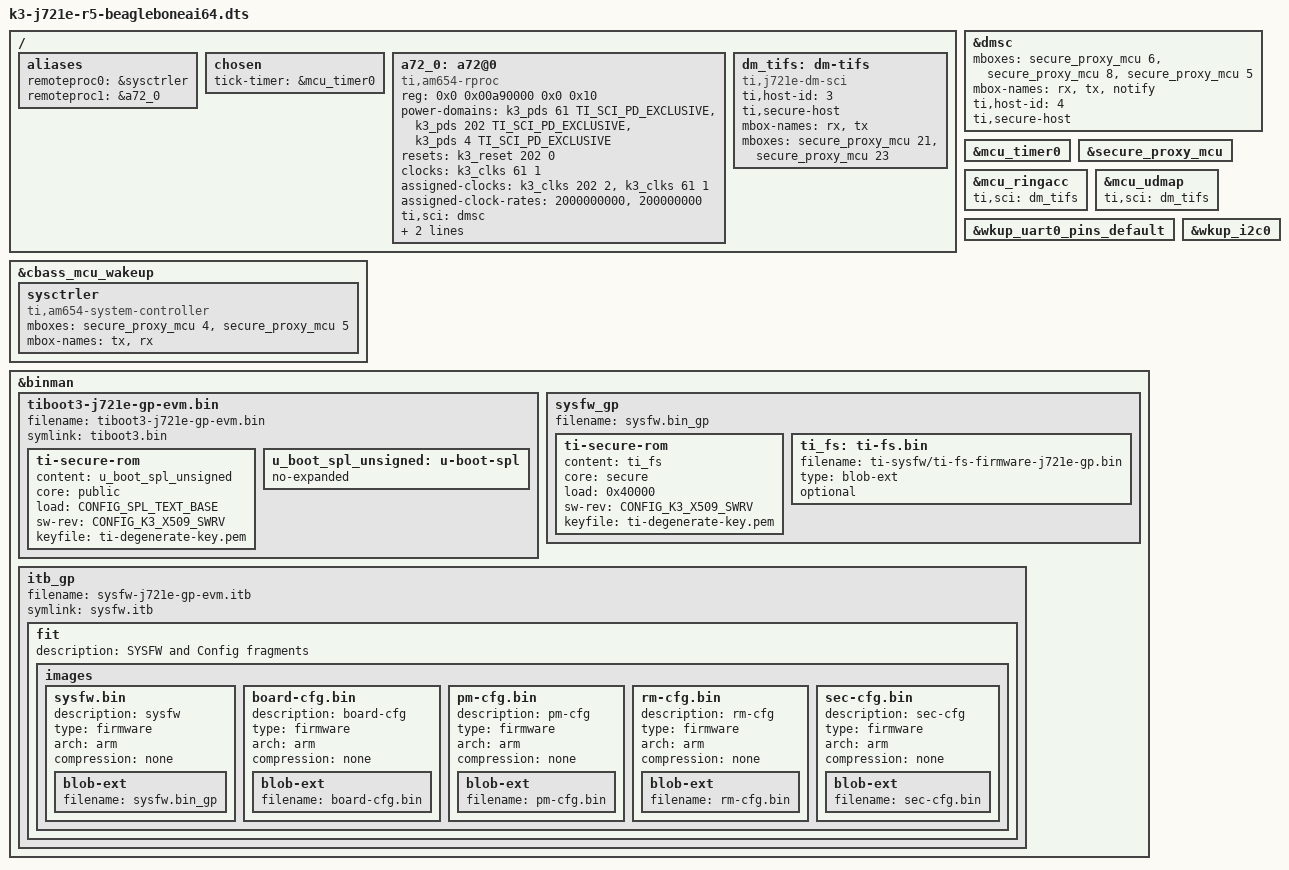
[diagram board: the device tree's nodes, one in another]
// SPDX-License-Identifier: GPL-2.0
/*
 * https://beagleboard.org/ai-64
 *
 * Copyright (C) 2022-2023 Texas Instruments Incorporated - https://www.ti.com/
 * Copyright (C) 2022 Jason Kridner, BeagleBoard.org Foundation
 * Copyright (C) 2022-2023 Robert Nelson, BeagleBoard.org Foundation
 */

#include "k3-j721e-beagleboneai64.dts"
#include "k3-j721e-ddr-beagleboneai64-lp4-3200.dtsi"
#include "k3-j721e-ddr.dtsi"

#include "k3-j721e-beagleboneai64-u-boot.dtsi"

/ {
	aliases {
		remoteproc0 = &sysctrler;
		remoteproc1 = &a72_0;
	};

	chosen {
		tick-timer = &mcu_timer0;
	};

	a72_0: a72@0 {
		compatible = "ti,am654-rproc";
		reg = <0x0 0x00a90000 0x0 0x10>;
		power-domains = <&k3_pds 61 TI_SCI_PD_EXCLUSIVE>,
				<&k3_pds 202 TI_SCI_PD_EXCLUSIVE>,
				<&k3_pds 4 TI_SCI_PD_EXCLUSIVE>;
		resets = <&k3_reset 202 0>;
		clocks = <&k3_clks 61 1>;
		assigned-clocks = <&k3_clks 202 2>, <&k3_clks 61 1>;
		assigned-clock-rates = <2000000000>, <200000000>;
		ti,sci = <&dmsc>;
		ti,sci-proc-id = <32>;
		ti,sci-host-id = <10>;
		bootph-pre-ram;
	};

	dm_tifs: dm-tifs {
		compatible = "ti,j721e-dm-sci";
		ti,host-id = <3>;
		ti,secure-host;
		mbox-names = "rx", "tx";
		mboxes= <&secure_proxy_mcu 21>,
				<&secure_proxy_mcu 23>;
		bootph-pre-ram;
	};
};

&dmsc {
	mboxes= <&secure_proxy_mcu 6>,
		<&secure_proxy_mcu 8>,
		<&secure_proxy_mcu 5>;
	mbox-names = "rx", "tx", "notify";
	ti,host-id = <4>;
	ti,secure-host;
};

&mcu_timer0 {
	status = "okay";
	bootph-pre-ram;
};

&secure_proxy_mcu {
	bootph-pre-ram;
	/* We require this for boot handshake */
	status = "okay";
};

&cbass_mcu_wakeup {
	sysctrler: sysctrler {
		compatible = "ti,am654-system-controller";
		mboxes= <&secure_proxy_mcu 4>, <&secure_proxy_mcu 5>;
		mbox-names = "tx", "rx";
		bootph-pre-ram;
	};
};

&mcu_ringacc {
	ti,sci = <&dm_tifs>;
};

&mcu_udmap {
	ti,sci = <&dm_tifs>;
};

&wkup_uart0_pins_default {
	bootph-pre-ram;
};

&wkup_i2c0 {
	bootph-pre-ram;
};

&binman {
	tiboot3-j721e-gp-evm.bin {
		filename = "tiboot3-j721e-gp-evm.bin";
		symlink = "tiboot3.bin";
		ti-secure-rom {
			content = <&u_boot_spl_unsigned>;
			core = "public";
			load = <CONFIG_SPL_TEXT_BASE>;
			sw-rev = <CONFIG_K3_X509_SWRV>;
			keyfile = "ti-degenerate-key.pem";
		};
		u_boot_spl_unsigned: u-boot-spl {
			no-expanded;
		};
	};

	sysfw_gp {
		filename = "sysfw.bin_gp";
		ti-secure-rom {
			content = <&ti_fs>;
			core = "secure";
			load = <0x40000>;
			sw-rev = <CONFIG_K3_X509_SWRV>;
			keyfile = "ti-degenerate-key.pem";
		};
		ti_fs: ti-fs.bin {
			filename = "ti-sysfw/ti-fs-firmware-j721e-gp.bin";
			type = "blob-ext";
			optional;
		};
	};

	itb_gp {
		filename = "sysfw-j721e-gp-evm.itb";
		symlink = "sysfw.itb";
		fit {
			description = "SYSFW and Config fragments";
			#address-cells = <1>;
			images {
				sysfw.bin {
					description = "sysfw";
					type = "firmware";
					arch = "arm";
					compression = "none";
					blob-ext {
					    filename = "sysfw.bin_gp";
					};
				};
				board-cfg.bin {
					description = "board-cfg";
					type = "firmware";
					arch = "arm";
					compression = "none";
					blob-ext {
						filename = "board-cfg.bin";
					};
				};
				pm-cfg.bin {
					description = "pm-cfg";
					type = "firmware";
					arch = "arm";
					compression = "none";
					blob-ext {
						filename = "pm-cfg.bin";
					};
				};
				rm-cfg.bin {
					description = "rm-cfg";
					type = "firmware";
					arch = "arm";
					compression = "none";
					blob-ext {
						filename = "rm-cfg.bin";
					};
				};
				sec-cfg.bin {
					description = "sec-cfg";
					type = "firmware";
					arch = "arm";
					compression = "none";
					blob-ext {
						filename = "sec-cfg.bin";
					};
				};
			};
		};
	};
};
